AUTOSAR XML (schema 4-2-2)
package /ComponentTypes
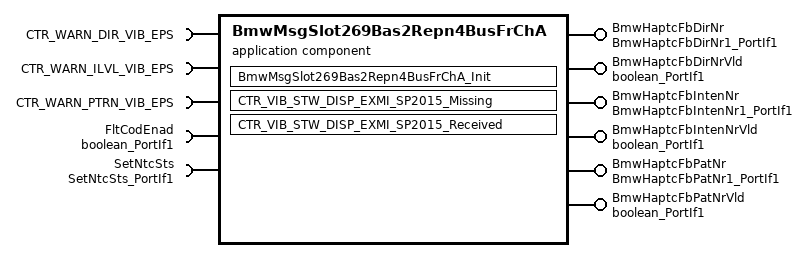
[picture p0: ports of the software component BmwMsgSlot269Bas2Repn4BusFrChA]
  application sw component type BmwMsgSlot269Bas2Repn4BusFrChA
    6 x provide port:
      BmwHaptcFbDirNr: nonqueued-sender-com-spec{data-element=Val, init-value=3}, provided-interface=BmwHaptcFbDirNr1_PortIf1
      BmwHaptcFbDirNrVld: nonqueued-sender-com-spec{data-element=Logl, init-value=0}, provided-interface=boolean_PortIf1
      BmwHaptcFbIntenNr: nonqueued-sender-com-spec{data-element=Val, init-value=15}, provided-interface=BmwHaptcFbIntenNr1_PortIf1
      BmwHaptcFbIntenNrVld: nonqueued-sender-com-spec{data-element=Logl, init-value=0}, provided-interface=boolean_PortIf1
      BmwHaptcFbPatNr: nonqueued-sender-com-spec{data-element=Val, init-value=15}, provided-interface=BmwHaptcFbPatNr1_PortIf1
      BmwHaptcFbPatNrVld: nonqueued-sender-com-spec{data-element=Logl, init-value=0}, provided-interface=boolean_PortIf1
    5 x require port:
      CTR_WARN_DIR_VIB_EPS: nonqueued-receiver-com-spec{data-element=CTR_WARN_DIR_VIB_EPS, alive-timeout=0.55, filter=data-filter-type=ALWAYS, init-value=3}, required-interface=CTR_WARN_DIR_VIB_EPS
      CTR_WARN_ILVL_VIB_EPS: nonqueued-receiver-com-spec{data-element=CTR_WARN_ILVL_VIB_EPS, alive-timeout=0.55, filter=data-filter-type=ALWAYS, init-value=15}, required-interface=CTR_WARN_ILVL_VIB_EPS
      CTR_WARN_PTRN_VIB_EPS: nonqueued-receiver-com-spec{data-element=CTR_WARN_PTRN_VIB_EPS, alive-timeout=0.55, filter=data-filter-type=ALWAYS, init-value=15}, required-interface=CTR_WARN_PTRN_VIB_EPS
      FltCodEnad: nonqueued-receiver-com-spec{data-element=Logl, filter=data-filter-type=ALWAYS, init-value=1}, required-interface=boolean_PortIf1
      SetNtcSts: client-com-spec=Oper, required-interface=SetNtcSts_PortIf1
    behavior BmwMsgSlot269Bas2Repn4BusFrChA_InternalBehavior
      ar-typed-per-instance-memorys:
        11 x data, all with sw-calibration-access=READ-ONLY:
          BmwHaptcFbDirNrPrev: type=BmwHaptcFbDirNr1
          BmwHaptcFbIntenNrPrev: type=BmwHaptcFbIntenNr1
          BmwHaptcFbPatNrPrev: type=BmwHaptcFbPatNr1
          CtrVibStwDispExmiSp2015MissFaild: type=uint8
          CtrVibStwDispExmiSp2015MissPassd: type=uint8
          CtrWarnDirVibEpsVldFaild: type=uint8
          CtrWarnDirVibEpsVldPassd: type=uint8
          CtrWarnIlvlVibEpsVldFaild: type=uint8
          CtrWarnIlvlVibEpsVldPassd: type=uint8
          CtrWarnPtrnVibEpsVldFaild: type=uint8
          CtrWarnPtrnVibEpsVldPassd: type=uint8
      init event BmwMsgSlot269Bas2Repn4BusFrChA_InitEvent: start-on-event=BmwMsgSlot269Bas2Repn4BusFrChA_Init
      data receive error event DRET_CTR_VIB_STW_DISP_EXMI_SP2015_Missing_CTR_WARN_DIR_VIB_EPS_CTR_WARN_DIR_VIB_EPS: start-on-event=CTR_VIB_STW_DISP_EXMI_SP2015_Missing, data=CTR_WARN_DIR_VIB_EPS.CTR_WARN_DIR_VIB_EPS
      data receive error event DRET_CTR_VIB_STW_DISP_EXMI_SP2015_Missing_CTR_WARN_ILVL_VIB_EPS_CTR_WARN_ILVL_VIB_EPS: start-on-event=CTR_VIB_STW_DISP_EXMI_SP2015_Missing, data=CTR_WARN_ILVL_VIB_EPS.CTR_WARN_ILVL_VIB_EPS
      data receive error event DRET_CTR_VIB_STW_DISP_EXMI_SP2015_Missing_CTR_WARN_PTRN_VIB_EPS_CTR_WARN_PTRN_VIB_EPS: start-on-event=CTR_VIB_STW_DISP_EXMI_SP2015_Missing, data=CTR_WARN_PTRN_VIB_EPS.CTR_WARN_PTRN_VIB_EPS
      data received event DRT_CTR_VIB_STW_DISP_EXMI_SP2015_Received_CTR_WARN_DIR_VIB_EPS_CTR_WARN_DIR_VIB_EPS: start-on-event=CTR_VIB_STW_DISP_EXMI_SP2015_Received, data=CTR_WARN_DIR_VIB_EPS.CTR_WARN_DIR_VIB_EPS
      data received event DRT_CTR_VIB_STW_DISP_EXMI_SP2015_Received_CTR_WARN_ILVL_VIB_EPS_CTR_WARN_ILVL_VIB_EPS: start-on-event=CTR_VIB_STW_DISP_EXMI_SP2015_Received, data=CTR_WARN_ILVL_VIB_EPS.CTR_WARN_ILVL_VIB_EPS
      data received event DRT_CTR_VIB_STW_DISP_EXMI_SP2015_Received_CTR_WARN_PTRN_VIB_EPS_CTR_WARN_PTRN_VIB_EPS: start-on-event=CTR_VIB_STW_DISP_EXMI_SP2015_Received, data=CTR_WARN_PTRN_VIB_EPS.CTR_WARN_PTRN_VIB_EPS
      port-api-options:
        enable-take-address=false, error-handling=NO-TRANSFORMER-ERROR-HANDLING, indirect-api=false, port=BmwHaptcFbDirNr
        enable-take-address=false, error-handling=NO-TRANSFORMER-ERROR-HANDLING, indirect-api=false, port=BmwHaptcFbDirNrVld
        enable-take-address=false, error-handling=NO-TRANSFORMER-ERROR-HANDLING, indirect-api=false, port=BmwHaptcFbIntenNr
        enable-take-address=false, error-handling=NO-TRANSFORMER-ERROR-HANDLING, indirect-api=false, port=BmwHaptcFbIntenNrVld
        enable-take-address=false, error-handling=NO-TRANSFORMER-ERROR-HANDLING, indirect-api=false, port=BmwHaptcFbPatNr
        enable-take-address=false, error-handling=NO-TRANSFORMER-ERROR-HANDLING, indirect-api=false, port=BmwHaptcFbPatNrVld
        enable-take-address=false, error-handling=NO-TRANSFORMER-ERROR-HANDLING, indirect-api=false, port=CTR_WARN_DIR_VIB_EPS
        enable-take-address=false, error-handling=NO-TRANSFORMER-ERROR-HANDLING, indirect-api=false, port=CTR_WARN_ILVL_VIB_EPS
        enable-take-address=false, error-handling=NO-TRANSFORMER-ERROR-HANDLING, indirect-api=false, port=CTR_WARN_PTRN_VIB_EPS
        enable-take-address=false, error-handling=NO-TRANSFORMER-ERROR-HANDLING, indirect-api=false, port=FltCodEnad
        enable-take-address=false, error-handling=NO-TRANSFORMER-ERROR-HANDLING, indirect-api=false, port=SetNtcSts
      runnable BmwMsgSlot269Bas2Repn4BusFrChA_Init
        sync call SC_SetNtcSts_Oper: operation=SetNtcSts.Oper, timeout=0
      runnable CTR_VIB_STW_DISP_EXMI_SP2015_Missing
        data-receive-point-by-arguments:
          access REC_FltCodEnad_Logl: accessed-variable=FltCodEnad.Logl
        data-send-points:
          6 x access:
            SEND_BmwHaptcFbDirNr_Val: accessed-variable=BmwHaptcFbDirNr.Val
            SEND_BmwHaptcFbDirNrVld_Logl: accessed-variable=BmwHaptcFbDirNrVld.Logl
            SEND_BmwHaptcFbIntenNr_Val: accessed-variable=BmwHaptcFbIntenNr.Val
            SEND_BmwHaptcFbIntenNrVld_Logl: accessed-variable=BmwHaptcFbIntenNrVld.Logl
            SEND_BmwHaptcFbPatNr_Val: accessed-variable=BmwHaptcFbPatNr.Val
            SEND_BmwHaptcFbPatNrVld_Logl: accessed-variable=BmwHaptcFbPatNrVld.Logl
        sync call SC_SetNtcSts_Oper: operation=SetNtcSts.Oper, timeout=0
      runnable CTR_VIB_STW_DISP_EXMI_SP2015_Received
        data-receive-point-by-arguments:
          4 x access:
            REC_CTR_WARN_DIR_VIB_EPS_CTR_WARN_DIR_VIB_EPS: accessed-variable=CTR_WARN_DIR_VIB_EPS.CTR_WARN_DIR_VIB_EPS
            REC_CTR_WARN_ILVL_VIB_EPS_CTR_WARN_ILVL_VIB_EPS: accessed-variable=CTR_WARN_ILVL_VIB_EPS.CTR_WARN_ILVL_VIB_EPS
            REC_CTR_WARN_PTRN_VIB_EPS_CTR_WARN_PTRN_VIB_EPS: accessed-variable=CTR_WARN_PTRN_VIB_EPS.CTR_WARN_PTRN_VIB_EPS
            REC_FltCodEnad_Logl: accessed-variable=FltCodEnad.Logl
        data-send-points:
          6 x access:
            SEND_BmwHaptcFbDirNr_Val: accessed-variable=BmwHaptcFbDirNr.Val
            SEND_BmwHaptcFbDirNrVld_Logl: accessed-variable=BmwHaptcFbDirNrVld.Logl
            SEND_BmwHaptcFbIntenNr_Val: accessed-variable=BmwHaptcFbIntenNr.Val
            SEND_BmwHaptcFbIntenNrVld_Logl: accessed-variable=BmwHaptcFbIntenNrVld.Logl
            SEND_BmwHaptcFbPatNr_Val: accessed-variable=BmwHaptcFbPatNr.Val
            SEND_BmwHaptcFbPatNrVld_Logl: accessed-variable=BmwHaptcFbPatNrVld.Logl
        sync call SC_SetNtcSts_Oper: operation=SetNtcSts.Oper, timeout=0
  swc implementation BmwMsgSlot269Bas2Repn4BusFrChA_Implementation: behavior=BmwMsgSlot269Bas2Repn4BusFrChA_InternalBehavior
    code-descriptors:
      code Default: artifact-descriptors=autosar-engineering-object={short-label=Default, category=SWSRC}
